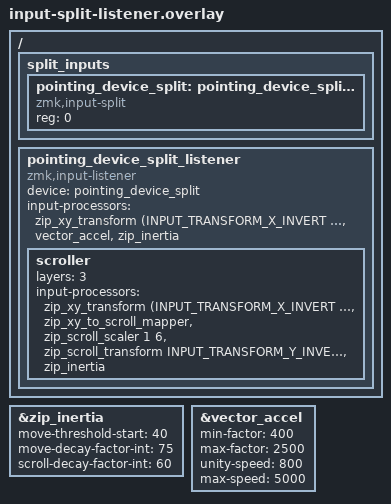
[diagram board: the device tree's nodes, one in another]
/{
    split_inputs {
        #address-cells = <1>;
        #size-cells = <0>;

        pointing_device_split: pointing_device_split@0 {
            compatible = "zmk,input-split";
            reg = <0>;
        };
    };

    pointing_device_split_listener: pointing_device_split_listener {
        compatible = "zmk,input-listener";
        device = <&pointing_device_split>;
        status = "okay";
        input-processors = <&zip_xy_transform (INPUT_TRANSFORM_X_INVERT | INPUT_TRANSFORM_Y_INVERT)>,
                           <&vector_accel>,
                           <&zip_inertia>;

        scroller {
            layers = <3>;
            input-processors = <&zip_xy_transform (INPUT_TRANSFORM_X_INVERT | INPUT_TRANSFORM_Y_INVERT)>,
                               <&zip_xy_to_scroll_mapper>,
                               <&zip_scroll_scaler 1 6>,
                               <&zip_scroll_transform INPUT_TRANSFORM_Y_INVERT>,
                               <&zip_inertia>;
        };
     };
};

// Tuning: tame scroll speed/coast and avoid move-inertia overshoot on
// precise, deliberate cursor positioning (see commit message).
&zip_inertia {
    move-threshold-start = <40>;
    move-decay-factor-int = <75>;
    scroll-decay-factor-int = <60>;
};

// Acceleration curve for normal cursor movement: slow, deliberate motion
// is scaled down for precise small-target aiming, a fast flick is scaled
// up so full-screen traversal still takes little physical movement.
// Starting values -- retune on hardware (see commit message).
&vector_accel {
    min-factor = <400>;
    max-factor = <2500>;
    unity-speed = <800>;
    max-speed = <5000>;
};
